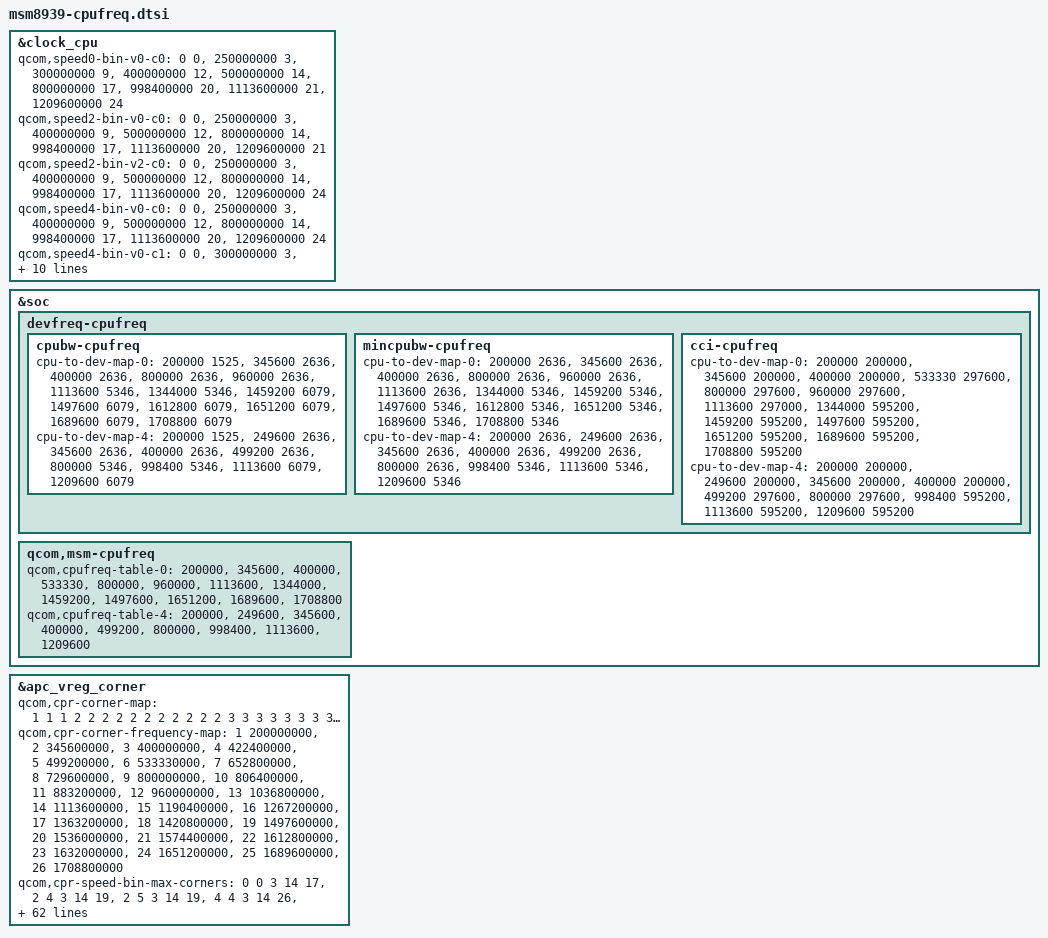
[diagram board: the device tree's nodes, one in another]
/*
 * Copyright (c) 2015, The Linux Foundation. All rights reserved.
 *
 * This program is free software; you can redistribute it and/or modify
 * it under the terms of the GNU General Public License version 2 and
 * only version 2 as published by the Free Software Foundation.
 *
 * This program is distributed in the hope that it will be useful,
 * but WITHOUT ANY WARRANTY; without even the implied warranty of
 * MERCHANTABILITY or FITNESS FOR A PARTICULAR PURPOSE.  See the
 * GNU General Public License for more details.
 */


&clock_cpu {
	qcom,speed0-bin-v0-c0 =
		<          0 0>,
		<  250000000 3>,
		<  300000000 9>,
		<  400000000 12>,
		<  500000000 14>,
		<  800000000 17>,
		<  998400000 20>,
		< 1113600000 21>,
		< 1209600000 24>;

	qcom,speed2-bin-v0-c0 =
		<          0 0>,
		<  250000000 3>,
		<  400000000 9>,
		<  500000000 12>,
		<  800000000 14>,
		<  998400000 17>,
		< 1113600000 20>,
		< 1209600000 21>;

	qcom,speed2-bin-v2-c0 =
		<          0 0>,
		<  250000000 3>,
		<  400000000 9>,
		<  500000000 12>,
		<  800000000 14>,
		<  998400000 17>,
		< 1113600000 20>,
		< 1209600000 24>;

	qcom,speed4-bin-v0-c0 =
		<          0 0>,
		<  250000000 3>,
		<  400000000 9>,
		<  500000000 12>,
		<  800000000 14>,
		<  998400000 17>,
		< 1113600000 20>,
		< 1209600000 24>;

	qcom,speed4-bin-v0-c1 =
		<          0 0>,
		<  300000000 3>,
		<  400000000 6>,
		<  600000000 9>,
		<  800000000 12>,
		<  960000000 14>,
		< 1113600000 16>,
		< 1344000000 17>,
		< 1459200000 19>,
		< 1497600000 20>,
		< 1612800000 21>,
		< 1651200000 23>,
		< 1689600000 24>,
		< 1708800000 26>;

	qcom,speed5-bin-v0-c0 =
		<          0 0>,
		<  250000000 3>,
		<  400000000 9>,
		<  500000000 12>,
		<  800000000 14>,
		<  998400000 17>,
		< 1113600000 20>,
		< 1209600000 24>;

	qcom,speed5-bin-v6-c0 =
		<          0 0>,
		<  250000000 3>,
		<  400000000 9>,
		<  500000000 12>,
		<  800000000 14>,
		<  998400000 17>,
		< 1113600000 20>,
		< 1209600000 24>;
};

&soc {
	devfreq-cpufreq {
		cpubw-cpufreq {
			cpu-to-dev-map-0 =
				<  200000  1525 >,
				<  345600  2636 >,
				<  400000  2636 >,
				<  800000  2636 >,
				<  960000  2636 >,
				<  1113600 5346 >,
				<  1344000 5346 >,
				<  1459200 6079 >,
				<  1497600 6079 >,
				<  1612800 6079 >,
				<  1651200 6079 >,
				<  1689600 6079 >,
				<  1708800 6079 >;

			cpu-to-dev-map-4 =
				<  200000 1525 >,
				<  249600 2636 >,
				<  345600 2636 >,
				<  400000 2636 >,
				<  499200 2636 >,
				<  800000 5346 >,
				<  998400 5346 >,
				< 1113600 6079 >,
				< 1209600 6079 >;
		};

		mincpubw-cpufreq {
			cpu-to-dev-map-0 =
				<  200000  2636 >,
				<  345600  2636 >,
				<  400000  2636 >,
				<  800000  2636 >,
				<  960000  2636 >,
				<  1113600 2636 >,
				<  1344000 5346 >,
				<  1459200 5346 >,
				<  1497600 5346 >,
				<  1612800 5346 >,
				<  1651200 5346 >,
				<  1689600 5346 >,
				<  1708800 5346 >;

			cpu-to-dev-map-4 =
				<  200000 2636 >,
				<  249600 2636 >,
				<  345600 2636 >,
				<  400000 2636 >,
				<  499200 2636 >,
				<  800000 2636 >,
				<  998400 5346 >,
				< 1113600 5346 >,
				< 1209600 5346 >;
		};

		cci-cpufreq {
			cpu-to-dev-map-0 =
				<  200000  200000 >,
				<  345600  200000 >,
				<  400000  200000 >,
				<  533330  297600 >,
				<  800000  297600 >,
				<  960000  297600 >,
				< 1113600  297000 >,
				< 1344000  595200 >,
				< 1459200  595200 >,
				< 1497600  595200 >,
				< 1651200  595200 >,
				< 1689600  595200 >,
				< 1708800  595200 >;

			cpu-to-dev-map-4 =
				<  200000 200000 >,
				<  249600 200000 >,
				<  345600 200000 >,
				<  400000 200000 >,
				<  499200 297600 >,
				<  800000 297600 >,
				<  998400 595200 >,
				< 1113600 595200 >,
				< 1209600 595200 >;
		};
	};

	qcom,msm-cpufreq {
		qcom,cpufreq-table-0 =
			<  200000 >,
			<  345600 >,
			<  400000 >,
			<  533330 >,
			<  800000 >,
			<  960000 >,
			< 1113600 >,
			< 1344000 >,
			< 1459200 >,
			< 1497600 >,
			< 1651200 >,
			< 1689600 >,
			< 1708800 >;
	
		qcom,cpufreq-table-4 =
			<  200000 >,
			<  249600 >,
			<  345600 >,
			<  400000 >,
			<  499200 >,
			<  800000 >,
			<  998400 >,
			< 1113600 >,
			< 1209600 >;
	};
};

&apc_vreg_corner {
		qcom,cpr-corner-map = <1 1 1 2 2 2 2 2 2 2 2 2 2 2 3 3 3 3 3 3
					3 3 3 3 3 3>;
		qcom,cpr-corner-frequency-map =
			<1 200000000>,
			<2 345600000>,
			<3 400000000>,
			<4 422400000>,
			<5 499200000>,
			<6 533330000>,
			<7 652800000>,
			<8 729600000>,
			<9 800000000>,
			<10 806400000>,
			<11 883200000>,
			<12 960000000>,
			<13 1036800000>,
			<14 1113600000>,
			<15 1190400000>,
			<16 1267200000>,
			<17 1363200000>,
			<18 1420800000>,
			<19 1497600000>,
			<20 1536000000>,
			<21 1574400000>,
			<22 1612800000>,
			<23 1632000000>,
			<24 1651200000>,
			<25 1689600000>,
			<26 1708800000>;
		qcom,cpr-speed-bin-max-corners =
					<0 0 3 14 17>,
					<2 4 3 14 19>,
					<2 5 3 14 19>,
					<4 4 3 14 26>,
					<5 4 3 14 24>,
					<5 5 3 14 24>;
		qcom,fuse-remap-base-row = <1000>;
		qcom,fuse-remap-source =
					<0 29 1 0>, /* speed bit[0] 	*/
					<0 50 2 0>, /* speed bit[2:1]	*/
					<0 45 1 0>, /* CPR Rev[0] 	*/
					<0 56 1 0>; /* CPR Rev[1]	*/
		qcom,pvs-version-fuse-sel = <1000 0 3 0>;
		qcom,cpr-fuse-revision = <1000 3 2 0>;
		qcom,cpr-fuse-version-map =
		/* <Speed_bits PVS_version CPR_Rev - - -> */
			<2          4          0 0xffffffff 0xffffffff 0xffffffff>,
			<2          4          1 0xffffffff 0xffffffff 0xffffffff>,
			<2          4          2 0xffffffff 0xffffffff 0xffffffff>,
			<2          4          3 0xffffffff 0xffffffff 0xffffffff>,
			<2          5          0 0xffffffff 0xffffffff 0xffffffff>,
			<2          5          1 0xffffffff 0xffffffff 0xffffffff>,
			<2          5          2 0xffffffff 0xffffffff 0xffffffff>,
			<2          5          3 0xffffffff 0xffffffff 0xffffffff>,
			<0xffffffff 0xffffffff 0 0xffffffff 0xffffffff 0xffffffff>,
			<0xffffffff 0xffffffff 1 0xffffffff 0xffffffff 0xffffffff>,
			<0xffffffff 0xffffffff 2 0xffffffff 0xffffffff 0xffffffff>,
			<0xffffffff 0xffffffff 3 0xffffffff 0xffffffff 0xffffffff>;
		qcom,cpr-init-voltage-adjustment =
					<0 50000 0>,
					<0 20000 0>,
					<0 50000 0>,
					<0 20000 0>,
					<0 50000 0>,
					<0 20000 0>,
					<0 50000 0>,
					<0 20000 0>,
					<0 50000 0>,
					<0 20000 0>,
					<0 50000 0>,
					<0 20000 0>;
		qcom,cpr-quotient-adjustment =
					<0   41  (-83)>, /* NOM + 20mv, TURBO - 40mv */
					<0 (-20) (-83)>, /* NOM - 10mv, TURBO - 40mv */
					<0  104  (-83)>, /* NOM + 50mv, TURBO - 40mv */
					<0   41  (-83)>, /* NOM + 20mv, TURBO - 40mv */
					<0   41  (-41)>, /* NOM + 20mv, TURBO - 20mv */
					<0 (-20) (-41)>, /* NOM - 10mv, TURBO - 20mv */
					<0  104  (-41)>, /* NOM + 50mv, TURBO - 20mv */
					<0   41  (-41)>, /* NOM + 20mv, TURBO - 20mv */
					<0   41  (-41)>, /* NOM + 20mv, TURBO - 20mv */
					<0 (-20) (-41)>, /* NOM - 10mv, TURBO - 20mv */
					<0  104  (-41)>, /* NOM + 50mv, TURBO - 20mv */
					<0   41  (-41)>; /* NOM + 20mv, TURBO - 20mv */
		qcom,cpr-fuse-min-quot-diff = <0 0 0>;
		qcom,cpr-min-quot-diff-adjustment =
					<0 0 40>,
					<0 0 40>,
					<0 0 40>,
					<0 0 40>,
					<0 0 40>,
					<0 0 40>,
					<0 0 40>,
					<0 0 40>,
					<0 0 40>,
					<0 0 40>,
					<0 0 40>,
					<0 0 40>;
		qcom,cpr-virtual-corner-quotient-adjustment =
			<0 0 0 (-104) (-104) (-104) (-104) (-104) (-104) (-104)
			 (-104) (-104) (-41) 0 0 0 0 0 0 0 0 0 0 0 0 0>,
			<0 0 0 (-104) (-104) (-104) (-104) (-104) (-104) (-104)
			 (-104) (-41) (-41) 0 0 0 0 0 0 0 0 0 0 0 0 0>,
			<0 0 0 (-104) (-104) (-104) (-104) (-104) (-104) (-104)
			 (-104) (-104) (-41) 0 0 0 0 0 0 0 0 0 0 0 0 0>,
			<0 0 0 (-104) (-104) (-104) (-104) (-104) (-104) (-104)
			 (-104) (-41) (-41) 0 0 0 0 0 0 0 0 0 0 0 0 0>,
			<0 0 0 (-104) (-104) (-104) (-104) (-104) (-104) (-104)
			 (-104) (-104) (-41) 0 0 0 0 0 0 0 0 113 0 0 0 0>,
			<0 0 0 (-104) (-104) (-104) (-104) (-104) (-104) (-104)
			 (-104) (-41) (-41) 0 0 0 0 0 0 0 0 113 0 0 0 0>,
			<0 0 0 (-104) (-104) (-104) (-104) (-104) (-104) (-104)
			 (-104) (-104) (-41) 0 0 0 0 0 0 0 0 113 0 0 0 0>,
			<0 0 0 (-104) (-104) (-104) (-104) (-104) (-104) (-104)
			 (-104) (-41) (-41) 0 0 0 0 0 0 0 0 113 0 0 0 0>,
			<0 0 0 (-104) (-104) (-104) (-104) (-104) (-104) (-104)
			 (-104) (-104) (-41) 0 0 0 0 0 0 0 0 0 0 0 0 0>,
			<0 0 0 (-104) (-104) (-104) (-104) (-104) (-104) (-104)
			 (-104) (-41) (-41) 0 0 0 0 0 0 0 0 0 0 0 0 0>,
			<0 0 0 (-104) (-104) (-104) (-104) (-104) (-104) (-104)
			 (-104) (-104) (-41) 0 0 0 0 0 0 0 0 0 0 0 0 0>,
			<0 0 0 (-104) (-104) (-104) (-104) (-104) (-104) (-104)
			 (-104) (-41) (-41) 0 0 0 0 0 0 0 0 0 0 0 0 0>;
		qcom,cpr-virtual-corner-init-voltage-adjustment =
			<0 0 0 0 0 0 0 0 0 0 0 0 0 0 0 0 0 0 0 0 0     0 0 0 0 0>,
			<0 0 0 0 0 0 0 0 0 0 0 0 0 0 0 0 0 0 0 0 0     0 0 0 0 0>,
			<0 0 0 0 0 0 0 0 0 0 0 0 0 0 0 0 0 0 0 0 0     0 0 0 0 0>,
			<0 0 0 0 0 0 0 0 0 0 0 0 0 0 0 0 0 0 0 0 0     0 0 0 0 0>,
			<0 0 0 0 0 0 0 0 0 0 0 0 0 0 0 0 0 0 0 0 0 35000 0 0 0 0>,
			<0 0 0 0 0 0 0 0 0 0 0 0 0 0 0 0 0 0 0 0 0 35000 0 0 0 0>,
			<0 0 0 0 0 0 0 0 0 0 0 0 0 0 0 0 0 0 0 0 0 35000 0 0 0 0>,
			<0 0 0 0 0 0 0 0 0 0 0 0 0 0 0 0 0 0 0 0 0 35000 0 0 0 0>,
			<0 0 0 0 0 0 0 0 0 0 0 0 0 0 0 0 0 0 0 0 0     0 0 0 0 0>,
			<0 0 0 0 0 0 0 0 0 0 0 0 0 0 0 0 0 0 0 0 0     0 0 0 0 0>,
			<0 0 0 0 0 0 0 0 0 0 0 0 0 0 0 0 0 0 0 0 0     0 0 0 0 0>,
			<0 0 0 0 0 0 0 0 0 0 0 0 0 0 0 0 0 0 0 0 0     0 0 0 0 0>;
		qcom,cpr-voltage-floor-override =
			<0xffffffff          5 1050000 1050000 1050000 1050000
			1050000 1050000 1050000 1050000 1050000 1050000 1050000
			1050000 1050000 1100000 1162500 1162500 1162500 1162500
			1162500 1162500 1162500 1162500 1162500 1162500 1162500
			1162500>,
			<0xffffffff 0xffffffff 1050000 1050000 1050000 1050000
			1050000 1050000 1050000 1050000 1050000 1050000 1050000
			1050000 1050000 1100000 1137500 1137500 1137500 1137500
			1137500 1137500 1137500 1137500 1137500 1137500 1137500
			1137500>;
};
